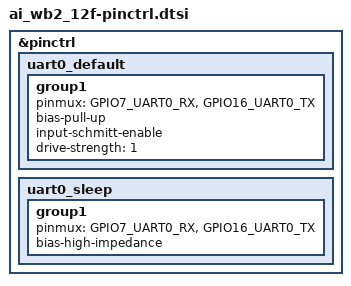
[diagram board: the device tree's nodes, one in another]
/*
 * Copyright (c) 2024, MASSDRIVER EI (massdriver.space)
 * SPDX-License-Identifier: Apache-2.0
 */


&pinctrl {
	uart0_default: uart0_default {
		group1 {
			pinmux = <GPIO7_UART0_RX>,
				 <GPIO16_UART0_TX>;
			bias-pull-up;
			input-schmitt-enable;
			drive-strength = <1>;
		};
	};

	uart0_sleep: uart0_sleep {
		group1 {
			pinmux = <GPIO7_UART0_RX>,
				 <GPIO16_UART0_TX>;
			bias-high-impedance;
		};
	};
};
